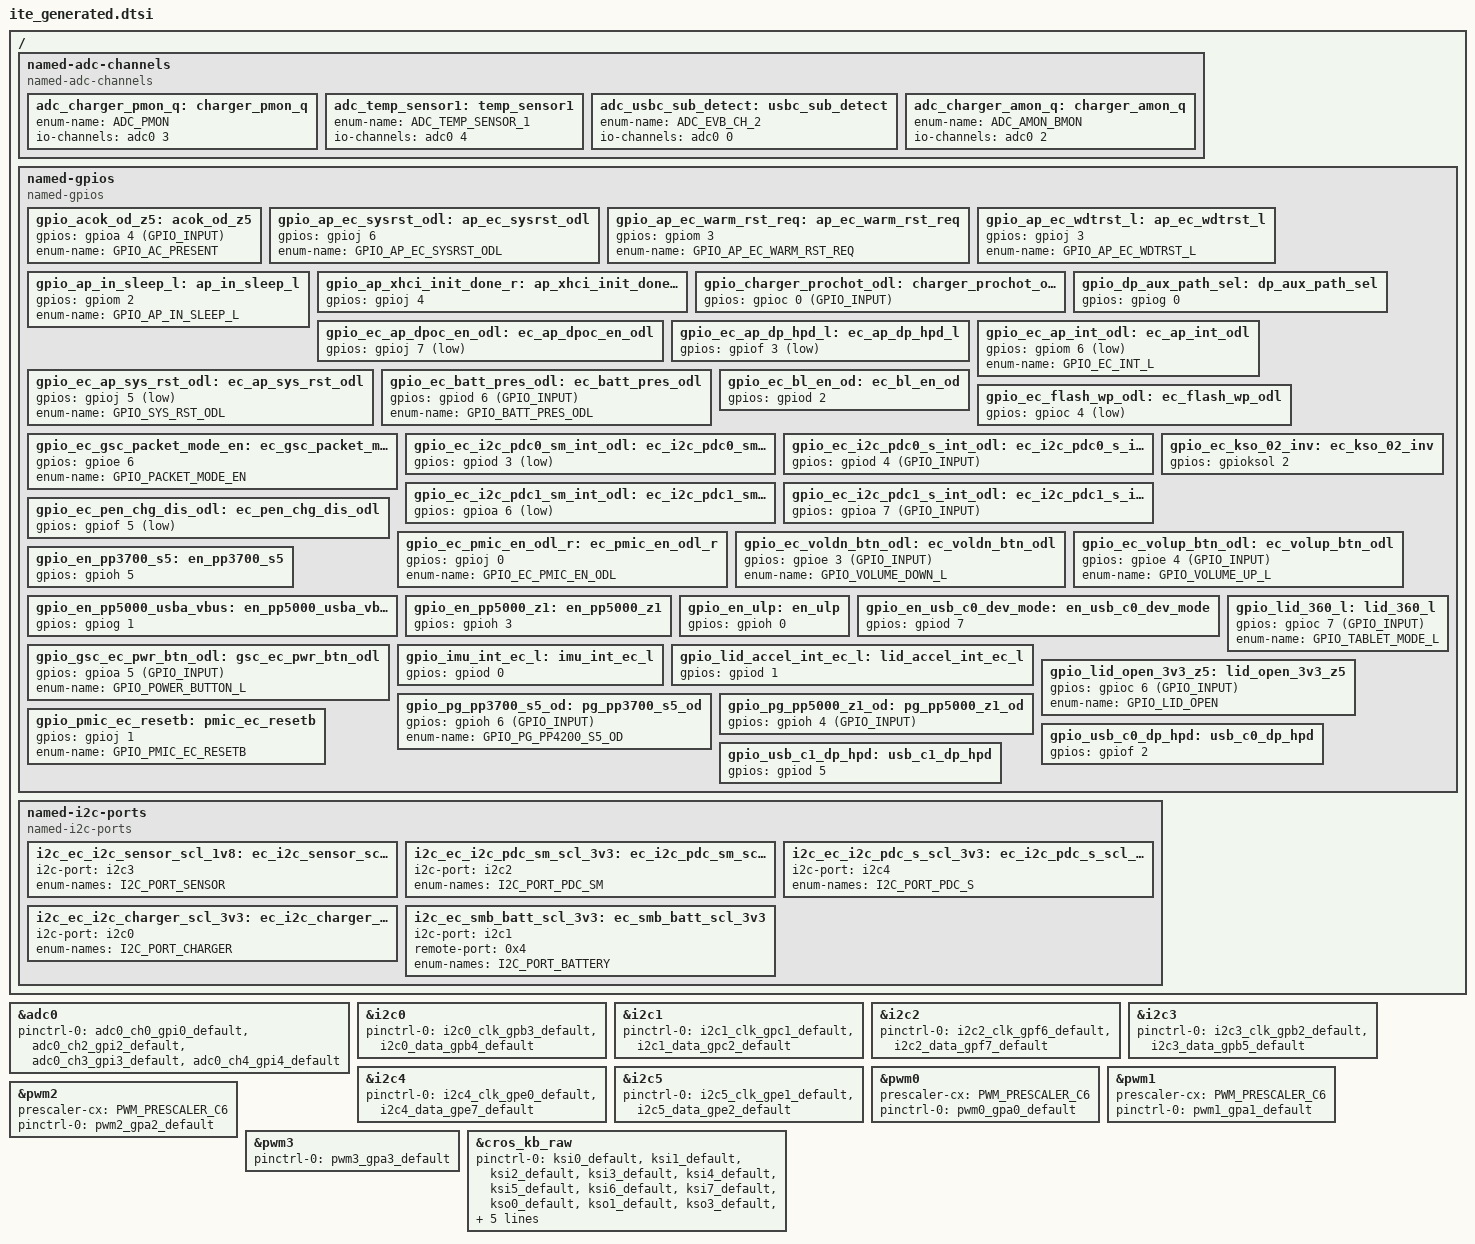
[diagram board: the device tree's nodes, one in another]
/* Copyright 2025 The ChromiumOS Authors
 * Use of this source code is governed by a BSD-style license that can be
 * found in the LICENSE file.
 *
 * This file is auto-generated - do not edit!
 */

/ {

	named-adc-channels {
		compatible = "named-adc-channels";

		adc_charger_pmon_q: charger_pmon_q {
			enum-name = "ADC_PMON";
			io-channels = <&adc0 3>;
		};
		adc_temp_sensor1: temp_sensor1 {
			enum-name = "ADC_TEMP_SENSOR_1";
			io-channels = <&adc0 4>;
		};
		adc_usbc_sub_detect: usbc_sub_detect {
			enum-name = "ADC_EVB_CH_2";
			io-channels = <&adc0 0>;
		};
		adc_charger_amon_q: charger_amon_q {
			enum-name = "ADC_AMON_BMON";
			io-channels = <&adc0 2>;
		};
	};

	named-gpios {
		compatible = "named-gpios";

		gpio_acok_od_z5: acok_od_z5 {
			gpios = <&gpioa 4 (GPIO_INPUT)>;
			enum-name = "GPIO_AC_PRESENT";
		};
		gpio_ap_ec_sysrst_odl: ap_ec_sysrst_odl {
			gpios = <&gpioj 6 (GPIO_INPUT | GPIO_VOLTAGE_1P8 )>;
			enum-name = "GPIO_AP_EC_SYSRST_ODL";
		};
		gpio_ap_ec_warm_rst_req: ap_ec_warm_rst_req {
			gpios = <&gpiom 3 (GPIO_INPUT | GPIO_VOLTAGE_1P8)>;
			enum-name = "GPIO_AP_EC_WARM_RST_REQ";
		};
		gpio_ap_ec_wdtrst_l: ap_ec_wdtrst_l {
			gpios = <&gpioj 3 (GPIO_INPUT | GPIO_VOLTAGE_1P8)>;
			enum-name = "GPIO_AP_EC_WDTRST_L";
		};
		gpio_ap_in_sleep_l: ap_in_sleep_l {
			gpios = <&gpiom 2 (GPIO_INPUT | GPIO_VOLTAGE_1P8)>;
			enum-name = "GPIO_AP_IN_SLEEP_L";
		};
		gpio_ap_xhci_init_done_r: ap_xhci_init_done_r {
			gpios = <&gpioj 4 (GPIO_INPUT | GPIO_VOLTAGE_1P8)>;
		};
		gpio_charger_prochot_odl: charger_prochot_odl {
			gpios = <&gpioc 0 (GPIO_INPUT)>;
		};
		gpio_dp_aux_path_sel: dp_aux_path_sel {
			gpios = <&gpiog 0 (GPIO_OUTPUT | GPIO_ACTIVE_HIGH | GPIO_OUTPUT_INIT_LOW)>;
		};
		gpio_ec_ap_dpoc_en_odl: ec_ap_dpoc_en_odl {
			gpios = <&gpioj 7 (GPIO_OUTPUT | GPIO_OPEN_DRAIN | GPIO_ACTIVE_LOW | GPIO_OUTPUT_INIT_HIGH)>;
		};
		gpio_ec_ap_dp_hpd_l: ec_ap_dp_hpd_l {
			gpios = <&gpiof 3 (GPIO_OUTPUT | GPIO_ACTIVE_LOW | GPIO_OUTPUT_INIT_HIGH)>;
		};
		gpio_ec_ap_int_odl: ec_ap_int_odl {
			gpios = <&gpiom 6 (GPIO_OUTPUT | GPIO_OPEN_DRAIN | GPIO_ACTIVE_LOW | GPIO_OUTPUT_INIT_HIGH)>;
			enum-name = "GPIO_EC_INT_L";
		};
		gpio_ec_ap_sys_rst_odl: ec_ap_sys_rst_odl {
			gpios = <&gpioj 5 (GPIO_OUTPUT | GPIO_OPEN_DRAIN | GPIO_ACTIVE_LOW | GPIO_OUTPUT_INIT_HIGH)>;
			enum-name = "GPIO_SYS_RST_ODL";
		};
		gpio_ec_batt_pres_odl: ec_batt_pres_odl {
			gpios = <&gpiod 6 (GPIO_INPUT)>;
			enum-name = "GPIO_BATT_PRES_ODL";
		};
		gpio_ec_bl_en_od: ec_bl_en_od {
			gpios = <&gpiod 2 (GPIO_OUTPUT | GPIO_OPEN_DRAIN | GPIO_ACTIVE_HIGH | GPIO_OUTPUT_INIT_LOW)>;
		};
		gpio_ec_flash_wp_odl: ec_flash_wp_odl {
			gpios = <&gpioc 4 (GPIO_INPUT | GPIO_ACTIVE_LOW)>;
		};
		gpio_ec_gsc_packet_mode_en: ec_gsc_packet_mode_en {
			gpios = <&gpioe 6 (GPIO_OUTPUT | GPIO_ACTIVE_HIGH | GPIO_OUTPUT_INIT_LOW)>;
			enum-name = "GPIO_PACKET_MODE_EN";
		};
		gpio_ec_i2c_pdc0_sm_int_odl: ec_i2c_pdc0_sm_int_odl {
			gpios = <&gpiod 3 (GPIO_INPUT | GPIO_ACTIVE_LOW)>;
		};
		gpio_ec_i2c_pdc0_s_int_odl: ec_i2c_pdc0_s_int_odl {
			gpios = <&gpiod 4 (GPIO_INPUT)>;
		};
		gpio_ec_i2c_pdc1_sm_int_odl: ec_i2c_pdc1_sm_int_odl {
			gpios = <&gpioa 6 (GPIO_INPUT | GPIO_ACTIVE_LOW)>;
		};
		gpio_ec_i2c_pdc1_s_int_odl: ec_i2c_pdc1_s_int_odl {
			gpios = <&gpioa 7 (GPIO_INPUT)>;
		};
		gpio_ec_kso_02_inv: ec_kso_02_inv {
			gpios = <&gpioksol 2 (GPIO_OUTPUT | GPIO_ACTIVE_HIGH | GPIO_OUTPUT_INIT_HIGH)>;
		};
		gpio_ec_pen_chg_dis_odl: ec_pen_chg_dis_odl {
			gpios = <&gpiof 5 (GPIO_OUTPUT | GPIO_OPEN_DRAIN | GPIO_ACTIVE_LOW | GPIO_OUTPUT_INIT_HIGH)>;
		};
		gpio_ec_pmic_en_odl_r: ec_pmic_en_odl_r {
			gpios = <&gpioj 0 (GPIO_OUTPUT | GPIO_OPEN_DRAIN | GPIO_ACTIVE_HIGH | GPIO_OUTPUT_INIT_HIGH)>;
			enum-name = "GPIO_EC_PMIC_EN_ODL";
		};
		gpio_ec_voldn_btn_odl: ec_voldn_btn_odl {
			gpios = <&gpioe 3 (GPIO_INPUT)>;
			enum-name = "GPIO_VOLUME_DOWN_L";
		};
		gpio_ec_volup_btn_odl: ec_volup_btn_odl {
			gpios = <&gpioe 4 (GPIO_INPUT)>;
			enum-name = "GPIO_VOLUME_UP_L";
		};
		gpio_en_pp3700_s5: en_pp3700_s5 {
			gpios = <&gpioh 5 (GPIO_OUTPUT | GPIO_ACTIVE_HIGH | GPIO_OUTPUT_INIT_LOW)>;
		};
		gpio_en_pp5000_usba_vbus: en_pp5000_usba_vbus {
			gpios = <&gpiog 1 (GPIO_OUTPUT | GPIO_ACTIVE_HIGH | GPIO_OUTPUT_INIT_LOW)>;
		};
		gpio_en_pp5000_z1: en_pp5000_z1 {
			gpios = <&gpioh 3 (GPIO_OUTPUT | GPIO_ACTIVE_HIGH | GPIO_OUTPUT_INIT_HIGH)>;
		};
		gpio_en_ulp: en_ulp {
			gpios = <&gpioh 0 (GPIO_OUTPUT | GPIO_ACTIVE_HIGH | GPIO_OUTPUT_INIT_LOW)>;
		};
		gpio_en_usb_c0_dev_mode: en_usb_c0_dev_mode {
			gpios = <&gpiod 7 (GPIO_OUTPUT | GPIO_ACTIVE_HIGH | GPIO_OUTPUT_INIT_LOW)>;
		};
		gpio_gsc_ec_pwr_btn_odl: gsc_ec_pwr_btn_odl {
			gpios = <&gpioa 5 (GPIO_INPUT)>;
			enum-name = "GPIO_POWER_BUTTON_L";
		};
		gpio_imu_int_ec_l: imu_int_ec_l {
			gpios = <&gpiod 0 (GPIO_INPUT | GPIO_VOLTAGE_1P8)>;
		};
		gpio_lid_360_l: lid_360_l {
			gpios = <&gpioc 7 (GPIO_INPUT)>;
			enum-name = "GPIO_TABLET_MODE_L";
		};
		gpio_lid_accel_int_ec_l: lid_accel_int_ec_l {
			gpios = <&gpiod 1 (GPIO_INPUT | GPIO_VOLTAGE_1P8)>;
		};
		gpio_lid_open_3v3_z5: lid_open_3v3_z5 {
			gpios = <&gpioc 6 (GPIO_INPUT)>;
			enum-name = "GPIO_LID_OPEN";
		};
		gpio_pg_pp3700_s5_od: pg_pp3700_s5_od {
			gpios = <&gpioh 6 (GPIO_INPUT)>;
			enum-name = "GPIO_PG_PP4200_S5_OD";
		};
		gpio_pg_pp5000_z1_od: pg_pp5000_z1_od {
			gpios = <&gpioh 4 (GPIO_INPUT)>;
		};
		gpio_pmic_ec_resetb: pmic_ec_resetb {
			gpios = <&gpioj 1 (GPIO_INPUT | GPIO_VOLTAGE_1P8)>;
			enum-name = "GPIO_PMIC_EC_RESETB";
		};
		gpio_usb_c0_dp_hpd: usb_c0_dp_hpd {
			gpios = <&gpiof 2 (GPIO_OUTPUT | GPIO_ACTIVE_HIGH | GPIO_OUTPUT_INIT_LOW)>;
		};
		gpio_usb_c1_dp_hpd: usb_c1_dp_hpd {
			gpios = <&gpiod 5 (GPIO_OUTPUT | GPIO_ACTIVE_HIGH | GPIO_OUTPUT_INIT_LOW)>;
		};
	};

	named-i2c-ports {
		compatible = "named-i2c-ports";

		i2c_ec_i2c_sensor_scl_1v8: ec_i2c_sensor_scl_1v8 {
			i2c-port = <&i2c3>;
			enum-names = "I2C_PORT_SENSOR";
		};
		i2c_ec_i2c_pdc_sm_scl_3v3: ec_i2c_pdc_sm_scl_3v3 {
			i2c-port = <&i2c2>;
			enum-names = "I2C_PORT_PDC_SM";
		};
		i2c_ec_i2c_pdc_s_scl_3v3: ec_i2c_pdc_s_scl_3v3 {
			i2c-port = <&i2c4>;
			enum-names = "I2C_PORT_PDC_S";
		};
		i2c_ec_i2c_charger_scl_3v3: ec_i2c_charger_scl_3v3 {
			i2c-port = <&i2c0>;
			enum-names = "I2C_PORT_CHARGER";
		};
		i2c_ec_smb_batt_scl_3v3: ec_smb_batt_scl_3v3 {
			i2c-port = <&i2c1>;
			remote-port = < 0x4 >;
			enum-names = "I2C_PORT_BATTERY";
		};
	};
};

&adc0 {
	status = "okay";
	pinctrl-0 = <&adc0_ch0_gpi0_default
		&adc0_ch2_gpi2_default
		&adc0_ch3_gpi3_default
		&adc0_ch4_gpi4_default>;
	pinctrl-names = "default";
};

&i2c0 {
	status = "okay";
	pinctrl-0 = <&i2c0_clk_gpb3_default
		&i2c0_data_gpb4_default>;
	pinctrl-names = "default";
};

&i2c1 {
	status = "okay";
	pinctrl-0 = <&i2c1_clk_gpc1_default
		&i2c1_data_gpc2_default>;
	pinctrl-names = "default";
};

&i2c2 {
	status = "okay";
	pinctrl-0 = <&i2c2_clk_gpf6_default
		&i2c2_data_gpf7_default>;
	pinctrl-names = "default";
};

&i2c3 {
	status = "okay";
	pinctrl-0 = <&i2c3_clk_gpb2_default
		&i2c3_data_gpb5_default>;
	pinctrl-names = "default";
};

&i2c4 {
	status = "okay";
	pinctrl-0 = <&i2c4_clk_gpe0_default
		&i2c4_data_gpe7_default>;
	pinctrl-names = "default";
};

&i2c5 {
	status = "okay";
	pinctrl-0 = <&i2c5_clk_gpe1_default
		&i2c5_data_gpe2_default>;
	pinctrl-names = "default";
};

&pwm0 {
	status = "okay";
	prescaler-cx = <PWM_PRESCALER_C6>;
	pinctrl-0 = <&pwm0_gpa0_default>;
	pinctrl-names = "default";
};

&pwm1 {
	status = "okay";
	prescaler-cx = <PWM_PRESCALER_C6>;
	pinctrl-0 = <&pwm1_gpa1_default>;
	pinctrl-names = "default";
};

&pwm2 {
	status = "okay";
	prescaler-cx = <PWM_PRESCALER_C6>;
	pinctrl-0 = <&pwm2_gpa2_default>;
	pinctrl-names = "default";
};

&pwm3 {
	status = "okay";
	pinctrl-0 = <&pwm3_gpa3_default>;
	pinctrl-names = "default";
};

&cros_kb_raw {
	status = "okay";
	pinctrl-0 = <&ksi0_default
		     &ksi1_default
		     &ksi2_default
		     &ksi3_default
		     &ksi4_default
		     &ksi5_default
		     &ksi6_default
		     &ksi7_default
		     &kso0_default
		     &kso1_default
		     &kso3_default
		     &kso4_default
		     &kso5_default
		     &kso6_default
		     &kso7_default
		     &kso8_default
		     &kso9_default
		     &kso10_default
		     &kso11_default
		     &kso12_default
		     &kso13_default
		     &kso14_default
		     &kso15_default
		     &kso16_default
		     &kso17_default>;
	pinctrl-names = "default";
};
